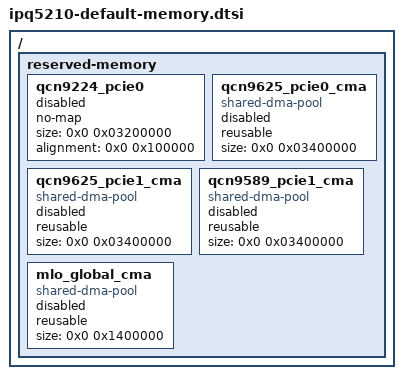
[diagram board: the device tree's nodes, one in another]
// SPDX-License-Identifier: (GPL-2.0+ OR BSD-3-Clause)
/*
 * IPQ5210 Memory device tree source
 *
 * Copyright (c) 2020-2021 The Linux Foundation. All rights reserved.
 * Copyright (c) Qualcomm Technologies, Inc. and/or its subsidiaries.
 */

/ {
	/*                Default Profile
	 * +==========+==============+========================+
	 * |         |              |                         |
	 * |  Region | Start Offset |          Size           |
	 * |         |              |                         |
	 * +---------+--------------+-------------------------+
	 * |         |              |                         |
	 * | QCN9224 |    DYNAMIC   |          50MB           |
	 * | PCIe0   |              |                         |
	 * |         |              |                         |
	 * +---------+--------------+-------------------------+
	 * |         |              |                         |
	 * | QCN9625 |    DYNAMIC   |          52MB           |
	 * | PCIe0   |              |                         |
	 * |         |              |                         |
	 * +---------+--------------+-------------------------+
	 * |         |              |                         |
	 * | QCN9625 |    DYNAMIC   |          52MB           |
	 * | PCIe1   |              |                         |
	 * |         |              |                         |
	 * +---------+--------------+-------------------------+
	 * |         |              |                         |
	 * | QCN9589 |    DYNAMIC   |          52MB           |
	 * | PCIe1   |              |                         |
	 * |         |              |                         |
	 * +---------+--------------+-------------------------+
	 * |         |              |                         |
	 * |  MLO    |    DYNAMIC   |          20MB           |
	 * |         |              |                         |
	 * +==================================================+
	 * |                                                  |
	 * |                                                  |
	 * |                                                  |
	 * |             Rest of memory for Linux             |
	 * |                                                  |
	 * |                                                  |
	 * |                                                  |
	 * +==================================================+
	 */

	reserved-memory {
		#address-cells = <2>;
		#size-cells = <2>;
		ranges;

		qcn9224_pcie0: qcn9224_pcie0 {
			no-map;
			size = <0x0 0x03200000>;
			alignment = <0x0 0x100000>;
			status = "disabled";
		};

		qcn9625_pcie0_cma: qcn9625_pcie0_cma {
			compatible = "shared-dma-pool";
			reusable;
			size = <0x0 0x03400000>;
			status = "disabled";
		};

		qcn9625_pcie1_cma: qcn9625_pcie1_cma {
			compatible = "shared-dma-pool";
			reusable;
			size = <0x0 0x03400000>;
			status = "disabled";
		};

		qcn9589_pcie1_cma: qcn9589_pcie1_cma {
			compatible = "shared-dma-pool";
			reusable;
			size = <0x0 0x03400000>;
			status = "disabled";
		};

		mlo_global_cma: mlo_global_cma {
			compatible = "shared-dma-pool";
			reusable;
			size = <0x0 0x1400000>;
			status = "disabled";
		};
	};
};
